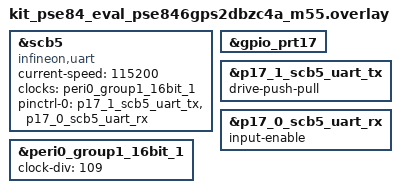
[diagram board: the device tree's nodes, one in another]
/*
 * SPDX-FileCopyrightText: Copyright (c) 2026 Infineon Technologies AG,
 * SPDX-FileCopyrightText: or an affiliate of Infineon Technologies AG. All rights reserved.
 *
 * SPDX-License-Identifier: Apache-2.0
 */

dut: &scb5 {
	compatible = "infineon,uart";
	status = "okay";
	current-speed = <115200>;
	clocks = <&peri0_group1_16bit_1>;
	pinctrl-0 = <&p17_1_scb5_uart_tx &p17_0_scb5_uart_rx>;
	pinctrl-names = "default";
};

&gpio_prt17 {
	status = "okay";
};

&p17_1_scb5_uart_tx {
	drive-push-pull;
};

&p17_0_scb5_uart_rx {
	input-enable;
};

&peri0_group1_16bit_1 {
	status = "okay";
	clock-div = <109>;
};
